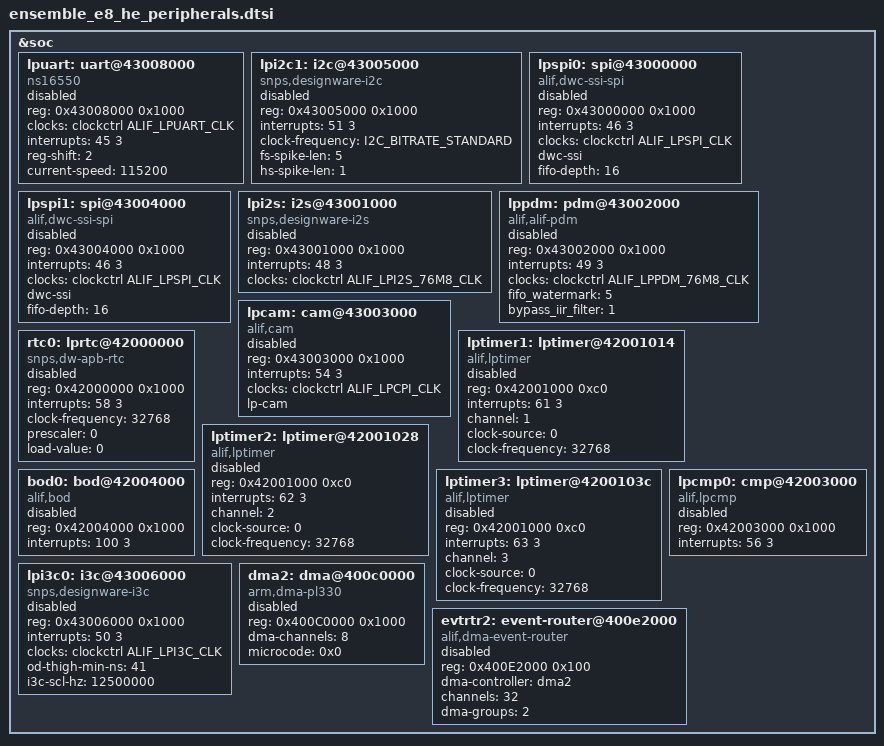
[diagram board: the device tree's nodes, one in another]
/*
 * Copyright (c) 2026 Alp Lab AB
 * SPDX-License-Identifier: Apache-2.0
 *
 * M55-HE-local peripherals of the Alif Ensemble E8 (AE822FA0E5597xx0): the
 * low-power peripheral bank (lpuart, lpi2c1, lpspi0/1, lpi2s, lppdm, lpcam),
 * rtc0, lptimer1..3, lpcmp0, bod0, lpi3c0, dma2 and its evtrtr2 event router.  Their interrupt numbers
 * are M55HE_IRQS[] vector-map lines and their registers are the HE-local
 * alias, so only the M55-HE boards include this file; on an M55-HP image the
 * NVIC lines would not match the HP vector map.  Included by the generated
 * alp_e1m_aen80x_m55_he boards after ensemble_e8_peripherals.dtsi.
 * Every node keeps the status it had in the shared file.  vendor-ext,
 * BENCH-UNVERIFIED.
 */

&soc {
	/*
	 * Low-power peripheral bank (M55-HE local domain, AE822 HWRM
	 * AHRM0012NDA v0.3 Table 10-5 Low Power Peripherals Memory Map, base
	 * 0x4300_0000) -- the wake-source / survivor set the datasheet
	 * (Alif_E8_Datasheet_v1.2, Table 3-3 footnote / Table 3-4) names: "If
	 * RTSS-HE is powered down, then the LPI3C, LPUTIMER, LPI2C1, LPCPI,
	 * LPI2S, LPPDM, and LPSPI0/1 in the same subsystem are also powered
	 * down" -- i.e. these are exactly what keeps running while the HP
	 * region, the NPUs and the main peripheral domain are off.  Every
	 * reg/IRQ below is transcribed from the HWRM: Table 10-5 for
	 * addresses, and the M55-HE local "Interrupt Input / Interrupt
	 * Number" table (M55HE_IRQS[45..58]) for IRQs -- the SAME table that
	 * already sources this file's existing lpi3c0 (50), rtc0/LPRTC (58)
	 * and lptimer0 (60) IRQs, so these numbers are cross-checked against
	 * three already-verified entries, not read cold.  Every node here is
	 * status="disabled", matching every other block in this file; a board
	 * enables the instances its firmware image uses.  vendor-ext,
	 * BENCH-UNVERIFIED.
	 *
	 * M55-HE ONLY: this file is included by the M55-HE boards alone, so an
	 * M55-HP image never sees these M55HE_IRQS[] vector-map lines or the
	 * HE-local register alias.  The same holds for dma2 (DMA2_SEC_BASE).
	 */

	/*
	 * LPUART -- HWRM: "All information related to UART in this section
	 * also applies to LPUART, unless stated otherwise" -- reachable with
	 * the SAME upstream "ns16550" driver as uart0..7 (Zephyr's
	 * ensemble_common.dtsi) -- Tier-1 upstream-native, no vendored code.
	 * reg 0x4300_8000/0x1000 (Table 10-5); IRQ 45 (M55HE_IRQS[45]
	 * LPUART_IRQ).  The clock gate is a DIFFERENT register from the
	 * M55-HE-local peripherals below: RTSS_HE_LPPERI_CKEN bit 0
	 * (UART_CKEN) in the AON block, not M55HE_CFG HE_CLK_ENA -- see
	 * ALIF_LPUART_CLK's own comment.  A STANDBY-mode wake source (Table
	 * 3-4).
	 */
	lpuart: uart@43008000 {
		compatible = "ns16550";
		reg = <0x43008000 0x1000>;
		clocks = <&clockctrl ALIF_LPUART_CLK>;
		interrupts = <45 3>;
		reg-shift = <2>;
		current-speed = <115200>;
		status = "disabled";
	};

	/*
	 * LPI2C1 -- MASTER-ONLY (HWRM I2C Overview: "Two Low-Power I2C
	 * modules (LPI2C0 slave-only and LPI2C1 master-only)... The I2C and
	 * LPI2C1 modules support the following main features" -- i.e. LPI2C1
	 * shares the regular I2C feature set, unlike the LPI2C0 SE-slave dead
	 * end the note below excludes).  Reachable with the SAME upstream
	 * "snps,designware-i2c" driver as i2c0/i2c1/i2c2 above -- Tier-1
	 * upstream-native.  reg 0x4300_5000/0x1000 (Table 10-5); IRQ 51
	 * (M55HE_IRQS[51] LPI2C1_IRQ).  No `clocks`: i2c_dw, like
	 * i2c0/i2c1/i2c2 above, consumes no clocks phandle -- even though a
	 * real software gate exists for this one (HE_CLK_ENA bit 13
	 * I2C_CKEN, reset 0, same register ALIF_LPSPI_CLK/ALIF_LPI3C_CLK use),
	 * left unmodelled/unwired for the same reason the main-domain i2c0/1/2
	 * gates are: the driver never asks for one.  Left undone, same class
	 * as the LPSPI0/LPSPI1 `HE_CLK_ENA[SPI_MODE]` gap noted below.
	 */
	lpi2c1: i2c@43005000 {
		compatible = "snps,designware-i2c";
		#address-cells = <1>;
		#size-cells = <0>;
		reg = <0x43005000 0x1000>;
		interrupts = <51 3>;
		clock-frequency = <I2C_BITRATE_STANDARD>;
		fs-spike-len = <5>;
		hs-spike-len = <1>;
		status = "disabled";
	};

	/*
	 * LPSPI0 (master) / LPSPI1 (slave) -- HWRM SPI Overview: "Up to two
	 * Low-Power SPI modules (LPSPI0 and LPSPI1) in the RTSS-HE, sharing
	 * device pins and thus forming a single LPSPI channel... Master mode
	 * only for LPSPI0, and Slave mode only for LPSPI1."  Both are the SAME
	 * DWC_ssi IP as spi0 above (compatible "alif,dwc-ssi-spi", dwc-ssi
	 * layout) -- Tier-2 interim, matching spi0's tier.  reg 0x4300_0000 /
	 * 0x4300_4000 (Table 10-5); BOTH share ONE physical IRQ line, 46
	 * (M55HE_IRQS[46] LPSPI_IRQ, "LPSPI0/1 interrupt request") -- not a
	 * typo, the silicon really ORs the two.  Mode selection between the
	 * pair is HE_CLK_ENA[SPI_MODE] (bit 15, a DIFFERENT bit from the
	 * SPI_CKEN gate ALIF_LPSPI_CLK already encodes) -- no DT property
	 * models it yet; an enabling board overlay needs that bit set
	 * correctly for whichever of the two it turns on, which is
	 * driver-level follow-up, not blocked by this disabled node.
	 */
	lpspi0: spi@43000000 {
		compatible = "alif,dwc-ssi-spi";
		#address-cells = <1>;
		#size-cells = <0>;
		reg = <0x43000000 0x1000>;
		interrupts = <46 3>;
		clocks = <&clockctrl ALIF_LPSPI_CLK>;
		dwc-ssi;
		fifo-depth = <16>;
		status = "disabled";
	};

	lpspi1: spi@43004000 {
		compatible = "alif,dwc-ssi-spi";
		#address-cells = <1>;
		#size-cells = <0>;
		reg = <0x43004000 0x1000>;
		interrupts = <46 3>;
		clocks = <&clockctrl ALIF_LPSPI_CLK>;
		dwc-ssi;
		fifo-depth = <16>;
		status = "disabled";
	};

	/*
	 * LPI2S -- reg 0x4300_1000/0x1000 (Table 10-5); IRQ 48
	 * (M55HE_IRQS[48] LPI2S_IRQ).  Same compatible as the main-domain i2s3
	 * node (examples/aen/aen-i2s-amp-alif overlay): "snps,designware-i2s"
	 * over the alp-sdk zephyr/drivers/i2s/i2s_dw.c driver.  Clock is
	 * ALIF_LPI2S_76M8_CLK (HE_I2S_CTRL bit 12 CLK_ENA + bit 16 CLK_SEL),
	 * mirroring the main-domain ALIF_I2Sx_76M8_CLK pattern.  No pinctrl-0:
	 * an enabling board overlay supplies the pad group.
	 */
	lpi2s: i2s@43001000 {
		compatible = "snps,designware-i2s";
		reg = <0x43001000 0x1000>;
		interrupts = <48 3>;
		clocks = <&clockctrl ALIF_LPI2S_76M8_CLK>;
		status = "disabled";
	};

	/*
	 * LPPDM -- the driver + Kconfig already exist (alif,alif-pdm,
	 * zephyr/drivers/audio/alif_pdm.c) and are already proven on the
	 * main-domain pdm@4902d000 node (examples/aen/aen-pdm-mic-alif
	 * overlay, which uses the SAME driver and cites this exact address in
	 * its own "NOT the LPPDM lppdm@43002000" comment) -- only the LP
	 * instance's node was missing.  reg 0x4300_2000/0x1000 (Table 10-5);
	 * clock ALIF_LPPDM_76M8_CLK (already defined -- HE_CLK_ENA bit 8
	 * PDM_CKEN + bit 9 PDM_CKSEL -- unused by any node until now).
	 * interrupts: ONE line, 49 (M55HE_IRQS[49] LPPDM_IRQ) -- the HWRM
	 * documents this as an OR of three internal sources (LPPDM_WARN_IRQ
	 * level, LPPDM_ERROR_IRQ edge, LPPDM_AUDIO_DET_IRQ edge), unlike the
	 * main-domain pdm node's THREE discrete IRQ lines (145/146/147) with
	 * matching interrupt-names "warning_intr"/"error_intr"/
	 * "audio_det_intr".  Only one line is given here since that is what
	 * LPPDM's silicon actually has; whether alif_pdm.c's IRQ_CONNECT count
	 * needs adjusting before this node can be enabled is driver-level
	 * follow-up, not modelled by this disabled node.
	 */
	lppdm: pdm@43002000 {
		compatible = "alif,alif-pdm";
		reg = <0x43002000 0x1000>;
		interrupts = <49 3>;
		clocks = <&clockctrl ALIF_LPPDM_76M8_CLK>;
		fifo_watermark = <5>;
		bypass_iir_filter = <1>;
		status = "disabled";
	};

	/*
	 * LPCPI -- the low-power camera-parallel-interface instance the
	 * alif,cam binding's `lp-cam` property already anticipates
	 * ("Signifies if the current CPI IP is LPCPI or normal CPI").  Same
	 * driver as the main-domain `cam` node below (alif,cam /
	 * video_alif.c) -- Tier-2 interim, matching cam's tier.  reg
	 * 0x4300_3000/0x1000 (Table 10-5); the LPCPI IRQ is named LPCAM_IRQ in
	 * the HWRM's M55-HE local IRQ table, number 54 (M55HE_IRQS[54]).
	 * Clock ALIF_LPCPI_CLK (HE_CLK_ENA bit 12 CPI_CKEN).  No pinctrl-0,
	 * matching cam: an enabling board overlay supplies the parallel-data
	 * pad group.
	 */
	lpcam: cam@43003000 {
		compatible = "alif,cam";
		reg = <0x43003000 0x1000>;
		interrupts = <54 3>;
		clocks = <&clockctrl ALIF_LPCPI_CLK>;
		clock-names = "cam_clk";
		lp-cam;
		status = "disabled";
	};

	/*
	 * LPRTC -- the always-on Synopsys DesignWare APB RTC at lprtc@42000000.
	 * Bound by the alp-sdk Tier-2 driver counter_dw_rtc.c (compatible
	 * "snps,dw-apb-rtc") as a Zephyr COUNTER device: a free-running 32-bit
	 * up-counter (CCVR) with ONE compare/alarm channel (CMR), clocked at
	 * 32768 Hz from the VBAT-domain LF source.  This is NOT a calendar RTC --
	 * it has no battery-backed date/time registers, so it does NOT satisfy the
	 * alp_rtc_* calendar surface as-is (the alp on-silicon RTC backend binds
	 * the Zephyr RTC *class* via the alp-rtc alias, which will not bind a
	 * counter; a counter->calendar shim backend is still TBD).  Surfaced to
	 * app code as an alp_counter via the alp-counter alias instead.
	 *
	 * reg/IRQ/clock transcribed VERBATIM from the Apache-2.0 zephyr_alif fork
	 * e1.dtsi (rtc0: lprtc@42000000; reg 0x42000000/0x1000; IRQ 58; 32768 Hz;
	 * prescaler 0; load-value 0).  The fork's ALIF_DEFAULT_IRQ_PRIORITY is
	 * rendered here as the repo's literal priority 3 (as the rest of this
	 * overlay does).
	 *
	 * CLOCK-GATE NOTE (BENCH-UNVERIFIED): the fork's SoC layer enables the
	 * LPRTC clock from VBAT when this node is okay (soc_common.c writes
	 * VBAT_LPRTC0_CLK_EN, 0x1A609010, iff rtc0 is okay).  alp-sdk builds
	 * against upstream Zephyr v4.4, whose ensemble soc.c does NOT do this
	 * write, and the driver does not write VBAT either -- so on this build path
	 * the gate is enabled by no visible code.  Confirm on the E8 bench whether
	 * the always-on VBAT domain already has it running (read CCVR; if it never
	 * advances, the VBAT gate is the cause).  Tier-2, INTERIM.
	 */
	/*
	 * SECONDARY RTC (#2784): not trusted for time or accurate timed wake -- Alif
	 * ER001 (A0: a STOP wake resets the prescaler), ER002 (A1: LFRC fallback) and
	 * the bench SES's "[SES] No LF XTAL".  The primary RTC is the on-module
	 * RV-3028 on BRD_I2C (INT -> P15_0 / LPGPIO0).
	 */
	rtc0: lprtc@42000000 {
		compatible = "snps,dw-apb-rtc";
		reg = <0x42000000 0x1000>;
		interrupts = <58 3>;
		clock-frequency = <32768>;
		prescaler = <0>;
		load-value = <0>;
		status = "disabled";
	};

	/*
	 * LPTIMER channels 1..3 -- the three sibling down-counters lptimer0's
	 * own comment above already documents ("to use another channel, set
	 * `channel` + its matching `interrupts`: ch1=61, ch2=62, ch3=63").
	 * `reg` is IDENTICAL to lptimer0's on every node below -- 0x42001000/
	 * 0xC0, the one block base -- and that is not a shortcut: the driver
	 * (counter_alif_lptimer.c, ch_base()) computes each channel's real
	 * register window at RUNTIME as `DT_INST_REG_ADDR(inst) + channel *
	 * LPTIMER_CHANNEL_STRIDE` (STRIDE = 0x14, counter_alif_lptimer.h),
	 * i.e. it ALREADY adds the per-channel offset itself from `channel`;
	 * `reg` is meant to stay at the block base for every channel node, not
	 * to be repointed per channel.  The stride itself IS real and
	 * documented -- HWRM Table 13-8 gives every LPTIMER register offset as
	 * "0x0 + (n x 0x14)" through "0x10 + (n x 0x14)", footnoted "n = 0 to
	 * 3, LPTIMER module index" -- so channel 1/2/3's real register windows
	 * are 0x42001014/0x42001028/0x4200103c, and THAT is what the
	 * unit-address below names (for humans/dtc node identity only, not as
	 * a `reg` override): Zephyr's edtlib requires a hex unit-address, and
	 * dtc requires unique node names, so "lptimer0..3" need distinct
	 * "lptimer@..." names or they collide as the same
	 * "lptimer@42001000".  Because the unit-address (the real per-channel
	 * window) does not match `reg` (the block base, correctly), dtc's
	 * simple_bus_reg check fires -- observed directly in a west build of
	 * this dtsi ("Warning (simple_bus_reg): /soc/lptimer@...: simple-bus
	 * unit address format error, expected 42001000"); non-fatal, expected,
	 * and left as-is rather than hidden.
	 */
	lptimer1: lptimer@42001014 {
		compatible = "alif,lptimer";
		reg = <0x42001000 0xc0>;
		interrupts = <61 3>;
		channel = <1>;
		clock-source = <0>;       /* 0 = 32 kHz VBAT LF source */
		clock-frequency = <32768>;
		status = "disabled";
	};

	lptimer2: lptimer@42001028 {
		compatible = "alif,lptimer";
		reg = <0x42001000 0xc0>;
		interrupts = <62 3>;
		channel = <2>;
		clock-source = <0>;       /* 0 = 32 kHz VBAT LF source */
		clock-frequency = <32768>;
		status = "disabled";
	};

	lptimer3: lptimer@4200103c {
		compatible = "alif,lptimer";
		reg = <0x42001000 0xc0>;
		interrupts = <63 3>;
		channel = <3>;
		clock-source = <0>;       /* 0 = 32 kHz VBAT LF source */
		clock-frequency = <32768>;
		status = "disabled";
	};

	/*
	 * LPCMP -- the Alif Ensemble Low-Power Comparator, a SINGLE instance
	 * in the VBAT/AON always-on island alongside LPRTC/LPTIMER/LPGPIO
	 * above -- a distinct, materially simpler IP from the four HSCMP
	 * instances (cmp0 below), so it does NOT reuse the alif,cmp binding;
	 * see zephyr/dts/bindings/comparator/alif,lpcmp.yaml for why (NO
	 * DRIVER exists for it yet -- issue #1817).  reg 0x4200_3000/0x1000
	 * (HWRM Table 10-4 Low Power VBAT Peripherals Memory Map); IRQ 56
	 * (M55HE_IRQS[56] LPCMP_IRQ, HWRM Table 19-25).  No `clocks`: HWRM
	 * Table 19-24 "LPCMP Clocks" names a single CLK32K (LFXO/LFRC-sourced)
	 * functional clock, gated by "LPCOMP_CLK32K_EN bit in the
	 * VBAT_ANA_REG1" per that table's own footnote -- a REAL software
	 * gate, just not the HE_CLK_ENA block the M55-HE-local peripherals
	 * above use, and not a register this dtsi's `clockctrl` node currently
	 * maps (VBAT_ANA_REG1 lives in the "ANA" block, HWRM Table 19-30, base
	 * 0x1A60A000 -- a DIFFERENT physical window from clockctrl's existing
	 * "vbat" reg region at 0x1A609000).  So the conclusion (no `clocks`
	 * phandle here) still holds; there is simply no gate to model until
	 * `clockctrl`/its driver grow an ANA-block case.  A STANDBY/STOP wake
	 * source (Datasheet Table 3-4).
	 */
	lpcmp0: cmp@42003000 {
		compatible = "alif,lpcmp";
		reg = <0x42003000 0x1000>;
		interrupts = <56 3>;
		status = "disabled";
	};

	/*
	 * BOD -- Brown-Out Detect, the programmable-threshold VDD_MAIN supply
	 * monitor.  The "BOD circuit monitors..." quote is Datasheet §3.7.4
	 * Power Supply Supervisors (NOT HWRM -- the HWRM covers this at
	 * §8.1.5 Power Supply Supervisors instead; it has no §3.7.4 at all).
	 * NO DRIVER exists for it yet -- see
	 * zephyr/dts/bindings/misc/alif,bod.yaml (issue #1817).  reg is the
	 * shared BOR_BOD block, 0x4200_4000/0x1000 (HWRM Table 10-4 + Table
	 * 19-32 BOR_BOD Modules); BOR (outright reset) is a separate concern
	 * and is NOT modelled by this node.  IRQ 100 (HWRM Table 8-5:
	 * `M55HE_IRQS[100]` BOD_IRQ -- NOT [99], a pdftotext column artifact
	 * in a different, jumbled interrupt-number table).  A STANDBY/STOP
	 * wake source (Datasheet §3.7.4 / Table 3-5 Power Supply Supervisory
	 * Functions) and a DMA request source: HWRM Table 8-6 gives the actual
	 * request number, `BOD_DMA_REQ` = `DMA2_REQ[7]` (Datasheet Table 3-5
	 * only says a DMA request exists, not which number) -- the DMA wiring
	 * is alp-sdk issue #1815's territory, not modelled here.
	 */
	bod0: bod@42004000 {
		compatible = "alif,bod";
		reg = <0x42004000 0x1000>;
		interrupts = <100 3>;
		status = "disabled";
	};

	/*
	 * LP I3C (M55-HE local domain) -- same upstream i3c_dw.c driver, a fully
	 * INDEPENDENT second controller.  It reaches P6_2/P6_3 (_A), P7_6/P7_7
	 * (_B) and P14_2/P14_3 (_C); the main i3c0 above reaches P0_0/P0_1,
	 * P1_2/P1_3, P3_2/P3_3 and P7_6/P7_7.  The two overlap on P7_6/P7_7
	 * ONLY, where the SoC exposes both PIN_P7_6__I3C_SDA_D/PIN_P7_7__I3C_SCL_D
	 * (fn6) and PIN_P7_6__LPI3C_SDA_B/PIN_P7_7__LPI3C_SCL_B (fn3).
	 *
	 * On the E1M-AEN801 that overlap is the whole story: the SoM breaks out
	 * only P7_6/P7_7, so exactly one of the two nodes may be enabled there.
	 * A board routing them to non-overlapping pads can run BOTH at once --
	 * do not read the AEN801 constraint as a silicon limit.
	 *
	 * Do NOT read that choice out of from-alif.tsv.  That table's
	 * `alif_peripheral` column (rows AG5/AH5) names the MAIN-I3C fn6
	 * functions, I3C_SCL_D/I3C_SDA_D, and the file contains no LPI3C row at
	 * all -- so if anything it documents i3c0, not this node.  lpi3c0 is
	 * preferred on E1M-AEN801 because it sits in the M55-HE local peripheral
	 * domain, a firmware/domain decision the pinout table does not make.
	 * reg/IRQ transcribed from the Apache-2.0 zephyr_alif fork
	 * (zephyr_alif@3a2b84d9, dts/arm/alif/ensemble/e4_e6_e8.dtsi:
	 * lpi3c0@0x43006000); od-thigh-min-ns/i3c-scl-hz carried over from the
	 * same fork node.  vendor-ext, BENCH-UNVERIFIED.
	 */
	lpi3c0: i3c@43006000 {
		compatible = "snps,designware-i3c";
		#address-cells = <3>;
		#size-cells = <0>;
		reg = <0x43006000 0x1000>;
		interrupts = <50 3>;
		clocks = <&clockctrl ALIF_LPI3C_CLK>;
		od-thigh-min-ns = <41>;
		i3c-scl-hz = <12500000>;
		status = "disabled";
	};

	/*
	 * ARM PL330 DMA controller -- the RTSS-core-LOCAL DMA.  On the E8 (AE822)
	 * each M55 cluster has its OWN PL330: the RTSS-HE core (this SoM's lead core)
	 * sees it as "DMA2", the RTSS-HP core sees its own as "DMA1"; BOTH sit at the
	 * same core-LOCAL register window 0x400C0000 (secure view) / 0x400E0000
	 * (non-secure view).  This node uses the secure-view local base 0x400C0000 --
	 * the address Alif's own PL330 driver instance prints ("Device
	 * dma2@400c0000 initialized", sdk-alif samples/drivers/dma_user_mcode/
	 * README.rst).  (The third controller, the GLOBAL "DMA0" at 0x49080000 sec /
	 * 0x490A0000 ns, is shared/cross-core and is NOT declared here.)
	 *
	 * Bound by UPSTREAM Zephyr v4.4's ARM PL330 driver (drivers/dma/dma_pl330.c,
	 * compatible "arm,dma-pl330") -- pure ADR 0017 Tier-1 (upstream-native): the
	 * standard Zephyr dma_* class device, no vendored / forked code.  The driver
	 * is a POLLING M2M DMA (dma_pl330_wait() spins on the channel-status CS0
	 * register) and uses NO `interrupts` / `clocks` -- the arm,dma-pl330 binding
	 * declares none, and the PL330 register block is always-clocked in the RTSS
	 * core domain.  (The DFP enumerates DMA2_IRQ0..IRQ31 = the 32 per-request
	 * event lines + DMA2_IRQ_ABORT_IRQn=32 in the RTSS-HE local IRQ space, used
	 * only by an IRQ-driven driver; the upstream polling driver needs none.)
	 *
	 * AUTHORITATIVE VALUES (Alif AE822 DFP, Device/soc/AE822FA0E5597/include/
	 * rtss_he/soc.h):
	 *   reg base 0x400C0000  -- DMA2_SEC_BASE (HP-side DMA1_SEC_BASE is the same
	 *                           0x400C0000).
	 *   dma-channels = <8>   -- the PL330 has 8 execution channels: the DFP DMA2
	 *                           register struct arrays DMA2_SEC_DMA_CHANNEL_RT_INFO
	 *                           DMA_CHANNEL_RT_INFO[8] / DMA_RT_CHANNEL_CFG[8]
	 *                           ([0..7]).
	 *
	 * `microcode` (required by arm,dma-pl330.yaml) -- a scratch RAM base the
	 * driver writes the generated per-channel microcode into (mcode_base; each of
	 * the 8 channels gets MICROCODE_SIZE_MAX=0x400 bytes -- dma_pl330.h -- so
	 * 8 * 0x400 = 0x2000).  The PL330 FETCHES that microcode over its own AXI
	 * master, so the region MUST be at a GLOBAL (AXI-visible) address -- NOT a
	 * core-local TCM alias.  Left as a placeholder 0 here so the disabled SoC node
	 * validates; an enabling board overlay sets it to a real carve-out in global
	 * SRAM0 (0x02000000, the sram0 node) AND places the DMA source/destination
	 * buffers there too (same global-address constraint -- the upstream PL330
	 * driver does NOT do the Alif local->global remap that the NPU/ETH paths use;
	 * see the aen-dma-regcheck overlay).
	 *
	 * A board enables this node (status="okay") + sets a real `microcode` address.
	 * ADR 0017 Tier-1 (upstream-native), BENCH-UNVERIFIED.
	 */
	dma2: dma@400c0000 {
		compatible = "arm,dma-pl330";
		reg = <0x400C0000 0x1000>; /* AE822 DFP rtss_he/soc.h: DMA2_SEC_BASE (M55-HE boots secure on the RAM-run) */
		/* AE822 DFP rtss_he/soc.h: DMA2_SEC DMA_CHANNEL_RT_INFO[8]/DMA_RT_CHANNEL_CFG[8] ([0..7]) */
		dma-channels = <8>;
		#dma-cells = <1>;
		/*
		 * microcode: AXI-visible scratch base for the 8*0x400 B generated channel
		 * ucode.  Placeholder 0; an enabling board overlay MUST point this at a
		 * real global-SRAM0 carve-out (the PL330 fetches ucode over AXI -- a
		 * core-local TCM alias is NOT reachable).
		 */
		microcode = <0x0>;
		status = "disabled";
	};

	/*
	 * EVTRTR2 -- the event router (DMA multiplexer) paired 1:1 with dma2
	 * above, per the AE822 HWRM §3.13.4 EVTRTR Overview: "EVTRTR2,
	 * dedicated to DMA2 controller and LPUTIMER."  Like dma2, it sits at a
	 * core-LOCAL register window (0x400E_2000, HWRM Table 10-8 M55-HE
	 * Local Memory Map) that the RTSS-HP core reaches at the SAME offset
	 * as its own local event router, EVTRTR1 (HWRM Table 10-7 M55-HP Local
	 * Memory Map: 0x400E_2000 too) -- exactly the dma2/"DMA1" aliasing
	 * dma2's own comment above already documents.  So this ONE node,
	 * `evtrtr2`, is what EVTRTR1 resolves to when this shared dtsi is
	 * built for the alp_e1m_aen801_m55_hp board; no separate evtrtr1 node
	 * is declared (it would collide with this one at the DT level, not
	 * extend it).
	 *
	 * dma-groups = 2: HWRM Table 12-31 "DMA2 (M55-HE) Requests Mapping" --
	 * "DMA requests to DMA2 controller are routed via 2-to-1 multiplexers
	 * as shown in Table 12-31. The selection of group 0-1 can be done
	 * independently for each DMA request via the corresponding
	 * EVTRTR2_DMA_CTRLn[SEL] field" -- i.e. TWO groups (0 and 1), not the
	 * aen-cc3501e-bringup overlay's SPI1-routing-comment prose ("1 group,
	 * for LP peripherals") this used to cite instead; that overlay comment
	 * describes evtrtr0's SYSTOP routing, not evtrtr2, and was the wrong
	 * source.  Peripheral request numbers on DMA2_REQ[n] for the LP bank
	 * above, cross-checked against Table 12-31 by row via two independent
	 * anchors (BOD_DMA_REQ at request 7, matching HWRM Table 8-6's
	 * `DMA2_REQ[7]`; LPGPIO_2..7_DMA_REQ at requests 26..31), for a future
	 * enabling board overlay to wire via `dmas`/`dma-names` (not done on
	 * any node here -- matching the existing precedent that `dmas` wiring
	 * is overlay-level, e.g. cc3501e_spi's dmas in the aen-cc3501e-bringup
	 * overlay, not SoC-dtsi-level): DMA2_REQ[12]/[13] LPSPI RX/TX (Group
	 * 0), DMA2_REQ[10] ADC24_DONE0 (Group 0; NOT [4] -- Table 12-31's
	 * request 4 is ADC120_DONE0_DMA_REQ, the main-domain 12-bit ADC).
	 * Disabled by default, matching dma2; an enabling board overlay flips
	 * both on together.
	 */
	evtrtr2: event-router@400e2000 {
		compatible = "alif,dma-event-router";
		reg = <0x400E2000 0x100>;
		dma-controller = <&dma2>;
		channels = <32>;
		dma-groups = <2>;
		#dma-cells = <2>;
		status = "disabled";
	};
};
